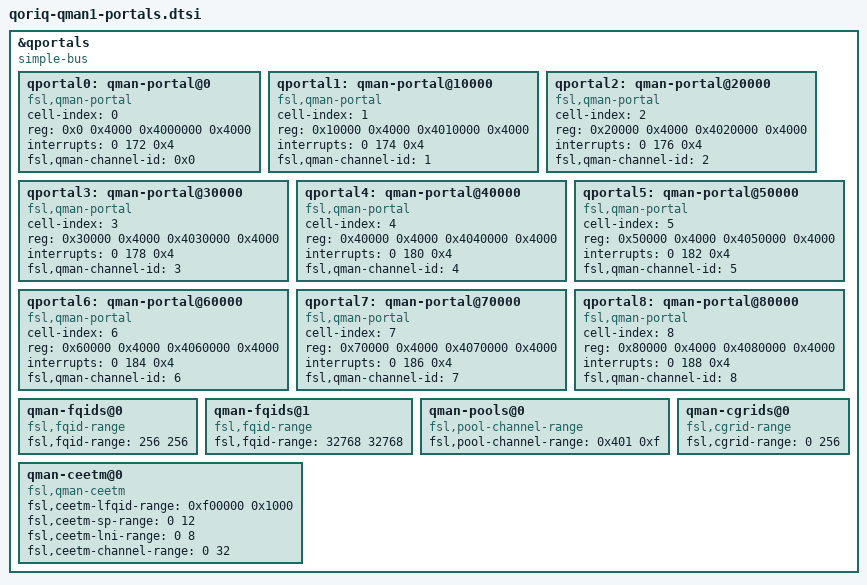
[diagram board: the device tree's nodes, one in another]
/*
 * QorIQ QMan Portal device tree stub for 10 portals & 15 pool channels
 *
 * Copyright 2011-2016 Freescale Semiconductor Inc.
 *
 * Redistribution and use in source and binary forms, with or without
 * modification, are permitted provided that the following conditions are met:
 *     * Redistributions of source code must retain the above copyright
 *	 notice, this list of conditions and the following disclaimer.
 *     * Redistributions in binary form must reproduce the above copyright
 *	 notice, this list of conditions and the following disclaimer in the
 *	 documentation and/or other materials provided with the distribution.
 *     * Neither the name of Freescale Semiconductor nor the
 *	 names of its contributors may be used to endorse or promote products
 *	 derived from this software without specific prior written permission.
 *
 *
 * ALTERNATIVELY, this software may be distributed under the terms of the
 * GNU General Public License ("GPL") as published by the Free Software
 * Foundation, either version 2 of that License or (at your option) any
 * later version.
 *
 * THIS SOFTWARE IS PROVIDED BY Freescale Semiconductor ``AS IS'' AND ANY
 * EXPRESS OR IMPLIED WARRANTIES, INCLUDING, BUT NOT LIMITED TO, THE IMPLIED
 * WARRANTIES OF MERCHANTABILITY AND FITNESS FOR A PARTICULAR PURPOSE ARE
 * DISCLAIMED. IN NO EVENT SHALL Freescale Semiconductor BE LIABLE FOR ANY
 * DIRECT, INDIRECT, INCIDENTAL, SPECIAL, EXEMPLARY, OR CONSEQUENTIAL DAMAGES
 * (INCLUDING, BUT NOT LIMITED TO, PROCUREMENT OF SUBSTITUTE GOODS OR SERVICES;
 * LOSS OF USE, DATA, OR PROFITS; OR BUSINESS INTERRUPTION) HOWEVER CAUSED AND
 * ON ANY THEORY OF LIABILITY, WHETHER IN CONTRACT, STRICT LIABILITY, OR TORT
 * (INCLUDING NEGLIGENCE OR OTHERWISE) ARISING IN ANY WAY OUT OF THE USE OF THIS
 * SOFTWARE, EVEN IF ADVISED OF THE POSSIBILITY OF SUCH DAMAGE.
 */
&qportals {

	  #address-cells = <1>;
	  #size-cells = <1>;
	  compatible = "simple-bus";
	  qportal0: qman-portal@0 {
		cell-index = <0>;
		compatible = "fsl,qman-portal";
		reg = <0x0 0x4000 0x4000000 0x4000>;
		interrupts = <0 172 0x4>;
		fsl,qman-channel-id = <0x0>;
	};

	qportal1: qman-portal@10000 {
		  cell-index = <1>;
		  compatible = "fsl,qman-portal";
		  reg = <0x10000 0x4000 0x4010000 0x4000>;
		  interrupts = <0 174 0x4>;
		  fsl,qman-channel-id = <1>;
	};

	qportal2: qman-portal@20000 {
		  cell-index = <2>;
		  compatible = "fsl,qman-portal";
		  reg = <0x20000 0x4000 0x4020000 0x4000>;
		  interrupts = <0 176 0x4>;
		  fsl,qman-channel-id = <2>;
	};

	qportal3: qman-portal@30000 {
		  cell-index = <3>;
		  compatible = "fsl,qman-portal";
		  reg = <0x30000 0x4000 0x4030000 0x4000>;
		  interrupts = <0 178 0x4>;
		  fsl,qman-channel-id = <3>;
	};

	qportal4: qman-portal@40000 {
		  cell-index = <4>;
		  compatible = "fsl,qman-portal";
		  reg = <0x40000 0x4000 0x4040000 0x4000>;
		  interrupts = <0 180 0x4>;
		  fsl,qman-channel-id = <4>;
	};

	qportal5: qman-portal@50000 {
		  cell-index = <5>;
		  compatible = "fsl,qman-portal";
		  reg = <0x50000 0x4000 0x4050000 0x4000>;
		  interrupts = <0 182 0x4>;
		  fsl,qman-channel-id = <5>;
	};

	qportal6: qman-portal@60000 {
		  cell-index = <6>;
		  compatible = "fsl,qman-portal";
		  reg = <0x60000 0x4000 0x4060000 0x4000>;
		  interrupts = <0 184 0x4>;
		  fsl,qman-channel-id = <6>;
	};

	qportal7: qman-portal@70000 {
		  cell-index = <7>;
		  compatible = "fsl,qman-portal";
		  reg = <0x70000 0x4000 0x4070000 0x4000>;
		  interrupts = <0 186 0x4>;
		  fsl,qman-channel-id = <7>;
	};

	qportal8: qman-portal@80000 {
		cell-index = <8>;
		compatible = "fsl,qman-portal";
		reg = <0x80000 0x4000 0x4080000 0x4000>;
		interrupts = <0 188 0x4>;
		fsl,qman-channel-id = <8>;
	};

/*	qportal9: qman-portal@90000 {
		cell-index = <9>;
		compatible = "fsl,qman-portal";
		reg = <0x90000 0x4000 0x4090000 0x4000>;
		interrupts = <0 190 0x4>;
		fsl,qman-channel-id = <9>;
	}; */

	qman-fqids@0 {
                compatible = "fsl,fqid-range";
                fsl,fqid-range = <256 256>;
        };
        qman-fqids@1 {
                compatible = "fsl,fqid-range";
                fsl,fqid-range = <32768 32768>;
        };
        qman-pools@0 {
                compatible = "fsl,pool-channel-range";
                fsl,pool-channel-range = <0x401 0xf>;
        };
        qman-cgrids@0 {
                compatible = "fsl,cgrid-range";
                fsl,cgrid-range = <0 256>;
        };
	qman-ceetm@0 {
		compatible = "fsl,qman-ceetm";
		fsl,ceetm-lfqid-range = <0xf00000 0x1000>;
		fsl,ceetm-sp-range = <0 12>;
		fsl,ceetm-lni-range = <0 8>;
		fsl,ceetm-channel-range = <0 32>;
	};
};
